VERSION ""

NS_ :

BS_:

BU_: Pi Test_Stand

BO_ 3221225472 VECTOR__INDEPENDENT_SIG_MSG: 0 Vector__XXX
 SG_ NewSignal_0004 : 40|8@1+ (1,0) [0|0] "" Vector__XXX

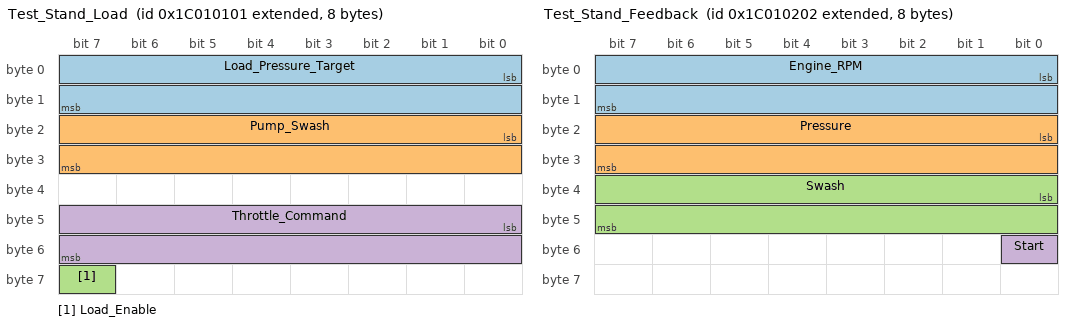
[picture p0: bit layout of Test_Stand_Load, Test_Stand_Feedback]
BO_ 2617311489 Test_Stand_Load: 8 Pi
 SG_ Load_Pressure_Target : 0|16@1+ (1,0) [0|3500] "" Vector__XXX
 SG_ Pump_Swash : 16|16@1+ (1,0) [0|10000] "" Vector__XXX
 SG_ Load_Enable : 63|1@1+ (1,0) [0|1] "" Vector__XXX
 SG_ Throttle_Command : 40|16@1+ (1,0) [0|26000] "" Vector__XXX

BO_ 2617311746 Test_Stand_Feedback: 8 Test_Stand
 SG_ Engine_RPM : 0|16@1+ (1,0) [0|3800] "" Vector__XXX
 SG_ Pressure : 16|16@1+ (1,0) [0|5000] "" Vector__XXX
 SG_ Swash : 32|16@1+ (1,0) [0|10000] "" Vector__XXX
 SG_ Start : 48|1@1+ (1,0) [0|1] "" Vector__XXX
